# GD32M53x register map
File version: 1.0
CPU: CM33 r2p1, little endian, MPU, FPU, DSP, 4 interrupt priority bits
Registers are 32-bit, read-write, reset 0x0 unless marked. A register's access mark holds for its fields unless they carry their own. Offsets are from the block's base; [hi:lo] are bit positions; {n}, {i} and the like mark numbered series; 'fields as' and 'values as' point back to an identical list.

## SYSCFG — System and memory architectur
Base 0x40010000
0x00 CFG0 ro — Configuration register 0
  [1:0] BOOT_MODE
0x04 CFG1 — Configuration register 1
  [0] I2CFMPEN — Enable Fast mode+ on I2C
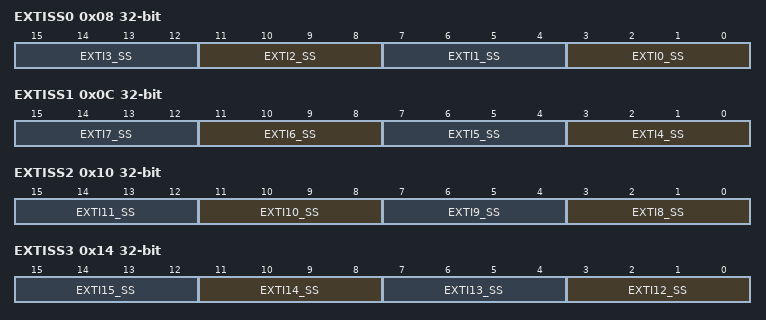
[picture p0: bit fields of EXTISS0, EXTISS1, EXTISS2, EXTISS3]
0x08 EXTISS0 — EXTI sources selection register 0
  [4n+3:4n] EXTI{n}_SS (n=0..3) — EXTI{n} sources selection
0x0C EXTISS1 — EXTI sources selection register 1
  [4n-13:4n-16] EXTI{n}_SS (n=4..7) — EXTI{n} sources selection
0x10 EXTISS2 — EXTI sources selection register 2
  [4n-29:4n-32] EXTI{n}_SS (n=8..11) — EXTI{n} sources selection
0x14 EXTISS3 — EXTI sources selection register 3
  [4n-45:4n-48] EXTI{n}_SS (n=12..15) — EXTI{n} sources selection
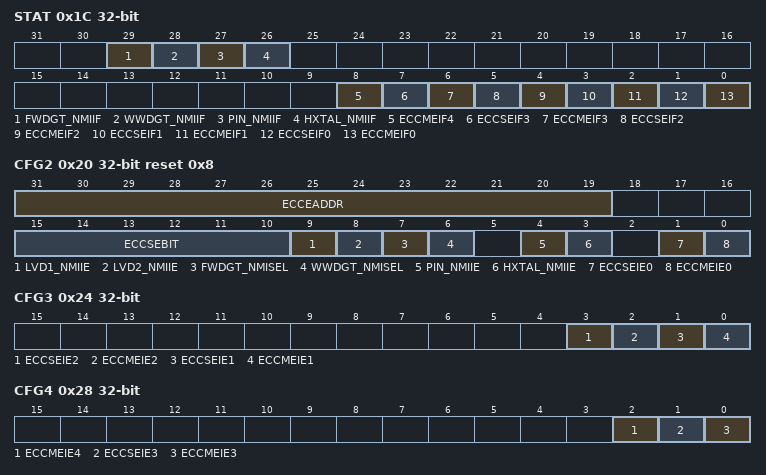
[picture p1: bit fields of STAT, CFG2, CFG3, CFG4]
0x1C STAT access per field — Status register
  [29] FWDGT_NMIIF rw — FWDGT NMI interrupt flag.
  [28] WWDGT_NMIIF ro — WWDGT NMI interrupt flag
  [27] PIN_NMIIF ro — Interrupt flag from NMI pin
  [26] HXTAL_NMIIF ro — HXTAL clock monitor NMI interrupt flag
  [8] ECCMEIF4 rw — Flash multi-bit non-correction error flag.
  [7] ECCSEIF3 rw — Flash SRAM single-bit correction error flag.
  [6] ECCMEIF3 rw — Flash SRAM multi-bit non-correction error flag.
  [5] ECCSEIF2 rw — CAN filter single-bit correction error flag.
  [4] ECCMEIF2 rw — CAN filter multi-bit non-correction error flag
  [3] ECCSEIF1 rw — CAN receive FIFO single-bit correction error flag
  [2] ECCMEIF1 rw — CAN receive FIFO multi-bit non-correction error flag
  [1] ECCSEIF0 rw — SRAM single-bit correction error flag
  [0] ECCMEIF0 rw — SRAM multi-bit non-correction error flag
0x20 CFG2 access per field reset 0x8 — Configuration register 2
  [31:19] ECCEADDR ro — Indicates the last address of ECC error on SRAM occurred.
  [15:10] ECCSEBIT ro — Indicates the error bit which one bit has an ECC single-bit correction error
  [9] LVD1_NMIIE rw — Low Voltage Detectors1 NMI interrupt enable
  [8] LVD2_NMIIE rw — Low Voltage Detectors2 NMI interrupt enable
  [7] FWDGT_NMISEL rw — FWDGT NMI interrupt type select
  [6] WWDGT_NMISEL rw — WWDGT NMI interrupt type select
  [4] PIN_NMIIE rw — NMI pin interrupt enable.
  [3] HXTAL_NMIIE rw — HXTAL clock monitor NMI interrupt enable.
  [1] ECCSEIE0 rw — SRAM single-bit correction interrupt enable
  [0] ECCMEIE0 rw — SRAM multi-bit non-correction interrupt enable
0x24 CFG3 — Configuration register 2
  [3] ECCSEIE2 — CAN filter single-bit correction interrupt enable
  [2] ECCMEIE2 — CAN filter multi-bit non-correction interrupt enable
  [1] ECCSEIE1 — CAN receive FIFO single-bit correction interrupt enable
  [0] ECCMEIE1 — CAN receive FIFO multi-bit non-correction interrupt enable
0x28 CFG4 — Configuration register 2
  [2] ECCMEIE4 — FLASH multi-bit non-correction interrupt enable
  [1] ECCSEIE3 — FLASH SRAM single-bit correction interrupt enable
  [0] ECCMEIE3 — FLASH SRAM multi-bit non-correction interrupt enable
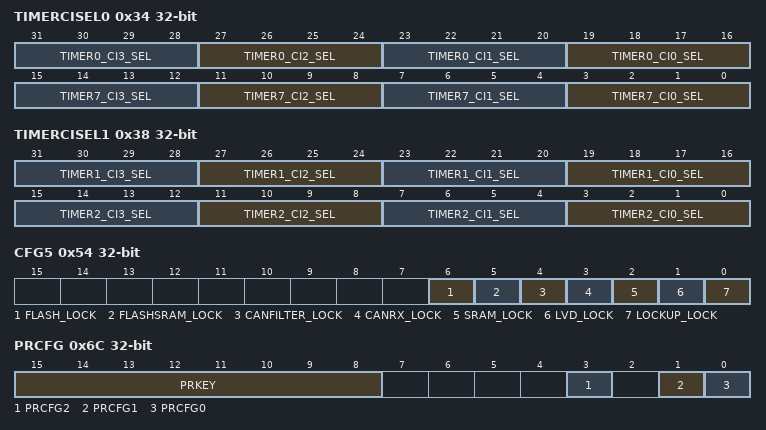
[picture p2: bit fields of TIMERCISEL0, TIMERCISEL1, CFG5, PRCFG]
0x34 TIMERCISEL0 — Timer input selection register 0
  [4n+19:4n+16] TIMER0_CI{n}_SEL (n=0..3) — Selects TIMER0_CI{n} input selection
  [4n+3:4n] TIMER7_CI{n}_SEL (n=0..3) — Selects TIMER7_CI{n} input selection
0x38 TIMERCISEL1 — Timer input selection register 1
  [4n+19:4n+16] TIMER1_CI{n}_SEL (n=0..3) — TIMER1_CI{n} input selection
  [4n+3:4n] TIMER2_CI{n}_SEL (n=0..3) — TIMER2_CI{n} input selection
0x54 CFG5 — Configuration register 5
  [6] FLASH_LOCK — Flash ECC multi-bit error lock.
  [5] FLASHSRAM_LOCK — Flash SRAM ECC multi-bit error lock.
  [4] CANFILTER_LOCK — CAN filter ECC multi-bit error lock
  [3] CANRX_LOCK — CAN receive FIFO ECC multi-bit error lock
  [2] SRAM_LOCK — SRAM ECC multi-bit error lock.
  [1] LVD_LOCK — Low voltage detector lock.
  [0] LOCKUP_LOCK — Cortex-M33 lockup (Hardfault) output lock.
0x68 SRAMCFG reset 0x3 — SRAM configuration register
  [1:0] SRAM_REMAP_SEL — This bit is used to control the size of SRAM aliased in 0x1000 0000 (remap of SRAM in 0x2000 0000). The CPU can access and SRAM aliased in 0x1000 0000 via CBUS instead of SBUS.
0x6C PRCFG — Protection configuration register
  [15:8] PRKEY — Protect area write key.
  [3] PRCFG2 — Protect configuration select 2.
  [1] PRCFG1 — Protect configuration select 1.
  [0] PRCFG0 — Protect configuration select 0.
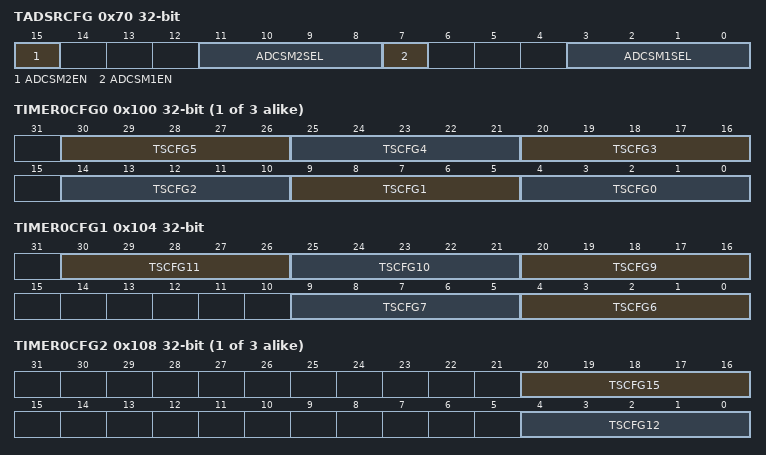
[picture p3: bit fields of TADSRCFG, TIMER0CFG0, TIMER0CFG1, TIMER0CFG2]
0x70 TADSRCFG — TIMERx ADC Start Request configuration Register
  [15] ADCSM2EN — ADCSM2 pin output enable
  [11:8] ADCSM2SEL — Select the ADC trigger source connected to ADCSM1 pin
  [7] ADCSM1EN — ADCSM1 pin output enable
  [3:0] ADCSM1SEL — Select the ADC trigger source connected to ADCSM1 pin
{0x100+0xC*i} TIMER{i}CFG0 (i=0..2) — TIMER{i} configuration register 0
  [30:26] TSCFG5 — Event mode configuration
  [25:21] TSCFG4 — Pause mode configuration
  [20:16] TSCFG3 — Restart mode configuration
  [14:10] TSCFG2 — Quadrature decoder mode 2 configuration
  [9:5] TSCFG1 — Quadrature decoder mode 1 configuration
  [4:0] TSCFG0 — Quadrature decoder mode 0 configuration
0x104 TIMER0CFG1 — TIMER0 configuration register 1
  [30:26] TSCFG11
  [25:21] TSCFG10
  [20:16] TSCFG9
  [9:5] TSCFG7 — Restart / event mode configuration
  [4:0] TSCFG6 — External clock mode 0 configuration
{0x108+0xC*i} TIMER{i}CFG2 (i=0..2) — TIMER{i} configuration register 2
  [20:16] TSCFG15 — Internal trigger input source configuration
  [4:0] TSCFG12 — Internal trigger input source configuration
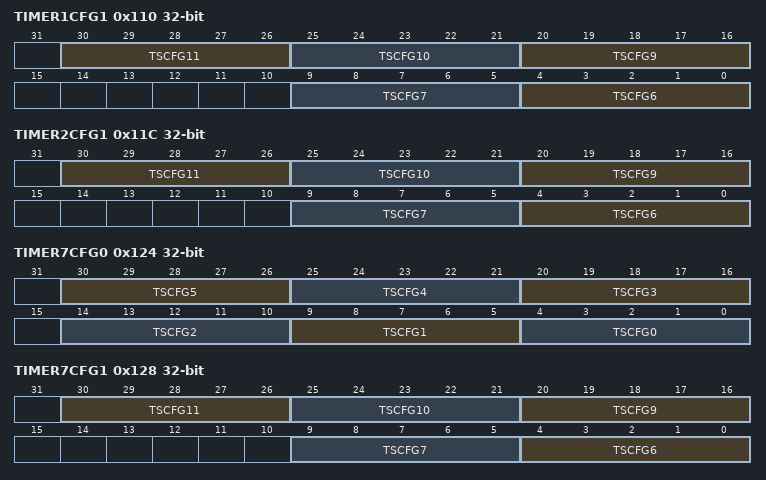
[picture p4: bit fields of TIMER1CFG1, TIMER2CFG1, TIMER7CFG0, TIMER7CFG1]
0x110 TIMER1CFG1 — TIMER1 configuration register 1
  [30:26] TSCFG11
  [25:21] TSCFG10
  [20:16] TSCFG9 — Non-quadrature decoder mode 1 configuration
  [9:5] TSCFG7 — Restart / event mode configuration
  [4:0] TSCFG6 — External clock mode 0 configuration
0x11C TIMER2CFG1 — TIMER2 configuration register 1
  fields as TIMER1CFG1
0x124 TIMER7CFG0 — TIMER7 configuration register 0
  fields as TIMER0CFG0
0x128 TIMER7CFG1 — TIMER7 configuration register 1
  fields as TIMER0CFG1
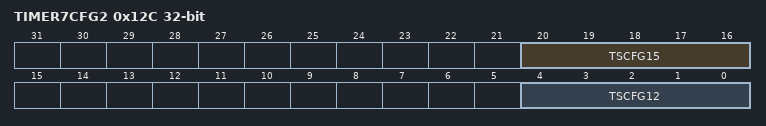
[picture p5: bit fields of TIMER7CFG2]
0x12C TIMER7CFG2 — TIMER7 configuration register 2
  fields as TIMER0CFG2
0x204 CFG6 — configuration register 6
  [0] CK_CMP_SEL — CK_CMP select
